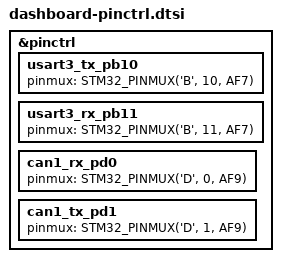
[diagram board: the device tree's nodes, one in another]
/*
 * Copyright (c) HyTech Racing
 * SPDX-License-Identifier: Apache-2.0
 */

/*
*TODO: please do pin control states. These are from base and we likely want something else
*/

&pinctrl {
    /* USART3 TX/RX (AF7) */
    usart3_tx_pb10: usart3_tx_pb10 {
        pinmux = <STM32_PINMUX('B', 10, AF7)>;
    };
    usart3_rx_pb11: usart3_rx_pb11 {
        pinmux = <STM32_PINMUX('B', 11, AF7)>;
    };

    /* CAN1 RX/TX (AF9) */
    can1_rx_pd0: can1_rx_pd0 {
        pinmux = <STM32_PINMUX('D', 0, AF9)>;
    };
    can1_tx_pd1: can1_tx_pd1 {
        pinmux = <STM32_PINMUX('D', 1, AF9)>;
    };
};

